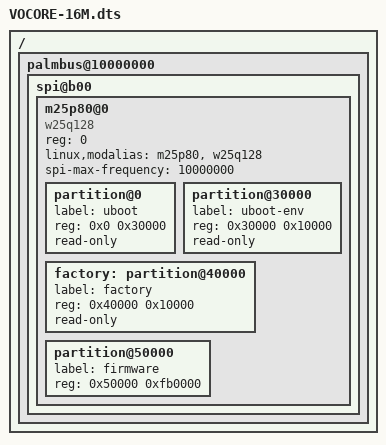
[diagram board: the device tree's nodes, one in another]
/dts-v1/;

/include/ "VOCORE.dtsi"

/ {
	palmbus@10000000 {
		spi@b00 {
			m25p80@0 {
				#address-cells = <1>;
				#size-cells = <1>;
				compatible = "w25q128";
				reg = <0>;
				linux,modalias = "m25p80", "w25q128";
				spi-max-frequency = <10000000>;

				partition@0 {
					label = "uboot";
					reg = <0x0 0x30000>;
					read-only;
				};

				partition@30000 {
					label = "uboot-env";
					reg = <0x30000 0x10000>;
					read-only;
				};

				factory: partition@40000 {
					label = "factory";
					reg = <0x40000 0x10000>;
					read-only;
				};

				partition@50000 {
					label = "firmware";
					reg = <0x50000 0xfb0000>;
				};
			};
		};
	};
};
